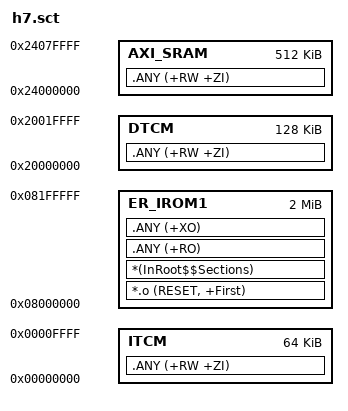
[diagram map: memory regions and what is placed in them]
; *************************************************************
; *** Scatter-Loading Description File generated by uVision ***
; *************************************************************

LR_IROM1 0x08000000 0x00200000  {    ; load region size_region
	ER_IROM1 0x08000000 0x00200000  {  ; load address = execution address
		*.o (RESET, +First)
		*(InRoot$$Sections)
		.ANY (+RO)
		.ANY (+XO)
	}
  
	ITCM 0x00000000 0x00010000  {  ; RW data 64kb
		.ANY (+RW +ZI)
	}
  
	DTCM 0x20000000 0x00020000  {  ; RW data 128kb
		.ANY (+RW +ZI)
	}
  
	AXI_SRAM 0x24000000 0x00080000  {  ; RW data D1 512kb
		.ANY (+RW +ZI)
	}
  ; AHB_SRAM1 0x30000000 0x00020000  {  ; RW data D2 128kb
  ;  .ANY (+RW)
  ; }
  ; AHB_SRAM2 0x30020000 0x00020000  {  ; RW data D2 128kb
  ;  .ANY (+RW)
  ; }
  ; AHB_SRAM3 0x30040000 0x00020000  {  ; RW data D2 32kb
  ;  .ANY (+RW)
  ; }
  ; AHB_SRAM4 0x38000000 0x00010000  {  ; RW data D2 64kb
  ;  .ANY (+RW)
  ; }
}
